# VPE_DEI register map
Vendor: Texas Instruments
Peripheral module from a debugger description file (folder TDA2Px).
Registers are 32-bit, access per field, reset 0x0 unless marked. A register's access mark holds for its fields unless they carry their own. Offsets are as the file gives them; lines under a group give offsets from that group; [hi:lo] are bit positions; {n}, {i} and the like mark numbered series; 'fields as' and 'values as' point back to an identical list; <NAME> marks a mode.

## VPE_DEI
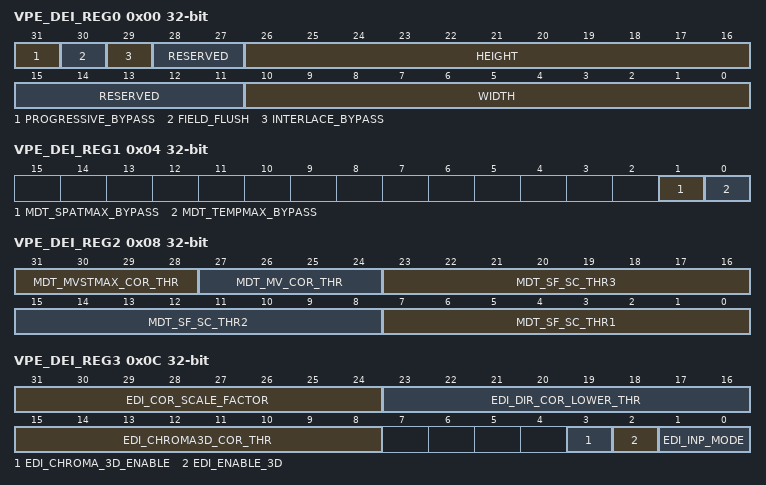
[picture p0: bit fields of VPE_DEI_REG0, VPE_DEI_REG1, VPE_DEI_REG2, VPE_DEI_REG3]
0x00 VPE_DEI_REG0
  [31] PROGRESSIVE_BYPASS rw — Progressive Mode
    0=Normal_Deinterlace_Mode; 1=Progressive_source
  [30] FIELD_FLUSH rw — Field Flush Mode
    0=Normal_Operation; 1=Flush Internal Pipe for Current output Frame
  [29] INTERLACE_BYPASS rw — Interlace Bypass Mode
    0=Normal_Deinterlace_Mode; 1=Pass Interlace Content directly to output
  [28:27] RESERVED ro — Always read as 0
  [26:16] HEIGHT rw — Frame Height
  [15:11] RESERVED ro — Always read as 0
  [10:0] WIDTH rw — Frame Width
0x04 VPE_DEI_REG1
  [1] MDT_SPATMAX_BYPASS rw — Spatial Maximum Filtering Bypass for motion values used in EDI
    0=Enable; 1=Bypass
  [0] MDT_TEMPMAX_BYPASS rw — Spatio-temporal Maximum Filtering Bypass for motion valued used in EDI
    0=Enable; 1=Bypass
0x08 VPE_DEI_REG2 rw
  [31:28] MDT_MVSTMAX_COR_THR — This is used for increasing noise robustness. Increasing this threshold leads to more robustness to noise, but with the potential of introducing ghosting effect. Note that this threshold is used for motion values for EDI only, and it is in addition mdt_mv_cor_thr.
  [27:24] MDT_MV_COR_THR — This threshold is for the coring for motion value, mv. MDT will become more noise robust if this value increases. But the picture may be washed out if this value is set to high. This threshold can be interpreted as the noise threshold for calculating motion values for all blocks.
  [23:16] MDT_SF_SC_THR3 — Spatial frequency threshold 3
  [15:8] MDT_SF_SC_THR2 — Spatial frequency threshold 2
  [7:0] MDT_SF_SC_THR1 — Spatial frequency threshold It is used for adaptive scaling of motion values according to how busy the texture is. If the texture is flat, motion values need to be scaled up to reflect the sensitivity of motion values with respect to the detection error. Increasing the thresholds will make the motion value scaling more sensitive to the frequency of the texture. Note: 0 = mdt_sf_sc_thr1 = mdt_sf_sc_thr2 = mdt_sf_sc_thr3
0x0C VPE_DEI_REG3
  [31:24] EDI_COR_SCALE_FACTOR rw — Scaling factor for correlation along detected edge
  [23:16] EDI_DIR_COR_LOWER_THR rw — Lower threshold used for correlation along detected edge
  [15:8] EDI_CHROMA3D_COR_THR rw — Correlation threshold used in 3D processing for chroma. Because the motion values used for chroma 3D processing are based on luma only. Extra protection is needed. Temporal interpolation is only performed for chroma, when there is strong spatial or temporal correlation for the chroma pixel being processed. When the pixel difference is less than this threshold, it is assumed that there exists strong correlation between these two pixels. Thus, increasing this value leads to more chroma pixels being processed in 3D
  [3] EDI_CHROMA_3D_ENABLE rw — 3D Chroma Enable
    0=Disable_3D_processing_for_chroma; 1=3D_1 (Enable 3D processing (temporal interpolation))
  [2] EDI_ENABLE_3D rw — 3D Enable
    0=Disable_3D_processing; 1=3D_1 (Enable 3D processing (temporal interpolation))
  [1:0] EDI_INP_MODE rw — Interpolation mode. Note that mode 00 and 01 are used for debug purpose
    0=line_average; 1=field_average; 2=edge-directed interpolation for luma only; 3=edge-directed interpolation for both luma and chroma
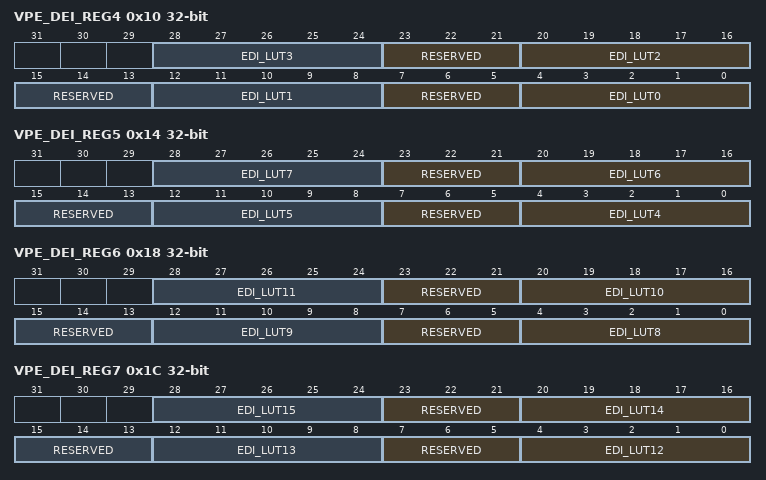
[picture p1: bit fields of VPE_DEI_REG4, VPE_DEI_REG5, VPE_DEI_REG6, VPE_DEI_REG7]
0x10 VPE_DEI_REG4
  [8n+4:8n] EDI_LUT{n} rw (n=0..3) — EDI Lookup Table {n}
  [23:21] RESERVED ro — Always read as 0
  [15:13] RESERVED ro — Always read as 0
  [7:5] RESERVED ro — Always read as 0
0x14 VPE_DEI_REG5
  [8n-28:8n-32] EDI_LUT{n} rw (n=4..7) — EDI Lookup Table {n}
  [23:21] RESERVED ro — Always read as 0
  [15:13] RESERVED ro — Always read as 0
  [7:5] RESERVED ro — Always read as 0
0x18 VPE_DEI_REG6
  [8n-60:8n-64] EDI_LUT{n} rw (n=8..11) — EDI Lookup Table {n}
  [23:21] RESERVED ro — Always read as 0
  [15:13] RESERVED ro — Always read as 0
  [7:5] RESERVED ro — Always read as 0
0x1C VPE_DEI_REG7
  [8n-92:8n-96] EDI_LUT{n} rw (n=12..15) — EDI Lookup Table {n}
  [23:21] RESERVED ro — Always read as 0
  [15:13] RESERVED ro — Always read as 0
  [7:5] RESERVED ro — Always read as 0
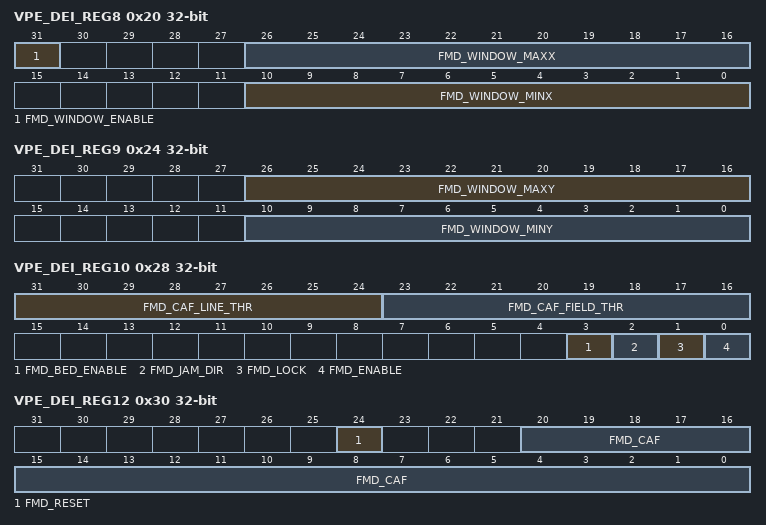
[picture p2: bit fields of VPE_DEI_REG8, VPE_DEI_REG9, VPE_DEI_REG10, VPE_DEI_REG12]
0x20 VPE_DEI_REG8
  [31] FMD_WINDOW_ENABLE rw — Enable FMD operation window
  [26:16] FMD_WINDOW_MAXX rw — Right boundary of FMD operation window Must be less than width
  [10:0] FMD_WINDOW_MINX rw — Left boundary of FMD operation window
0x24 VPE_DEI_REG9
  [26:16] FMD_WINDOW_MAXY rw — Bottom boundary of FMD operation window Must be less than height/2
  [10:0] FMD_WINDOW_MINY rw — Top boundary of FMD operation window
0x28 VPE_DEI_REG10
  [31:24] FMD_CAF_LINE_THR rw — CAF threshold used for the pixels from two lines in one field This is the threshold used for combing artifacts detection. The difference of two consecutive lines from the same field (so there is one line in between if two fields are merged into one progressive frame) is compared with this threshold. Decreasing this threshold leads to be more conservative in detecting CAF. Both fmd_caf_field_thr and fmd_caf_line_thr are close the values that two pixels differed by this value is observable.
  [23:16] FMD_CAF_FIELD_THR rw — CAF threshold used for the pixels from two fields This is the threshold used for combing artifacts detection. The difference of two consecutive lines (when merging two fields into one progressive frame) is used to compare with this threshold. Increasing this threshold leads to be more conservative in detecting CAF.
  [3] FMD_BED_ENABLE rw — Film Mode Bad Edit Detection
    0=Disable; 1=Enable
  [2] FMD_JAM_DIR rw — Film Mode Field Jamming Direction
    0=Current field jammed with previous field; 1=Current_field_jammed_with_next_field
  [1] FMD_LOCK rw — Film Mode Field Jamming Direction
    values as FMD_JAM_DIR
  [0] FMD_ENABLE rw — Enable film mode processing
    0=Disable; 1=Enable
0x2C VPE_DEI_REG11
  [19:0] FMD_CAF_THR rw — CAF threshold used for leaving film mode: If the combing artifacts is greater than this threshold, CAF is detected and thus the state machine will be forced to leave the film mode. If the user prefers to be more conservative in using film mode, decrease this threshold.
0x30 VPE_DEI_REG12 ro
  [24] FMD_RESET — When “1”, the film mode detection module needs to be reset by the software. This bit needs to be checked at each occurrence of the film mode detection interrupt
  [20:0] FMD_CAF — Detected combing artifacts
0x34 VPE_DEI_REG13 ro
  [27:0] FMD_FIELD_DIFF — Field difference (difference between two neighboring fields, one top and one bottom)
0x38 VPE_DEI_REG14 ro
  [19:0] FMD_FRAME_DIFF — Frame difference (difference between two top or two bottom fields)
